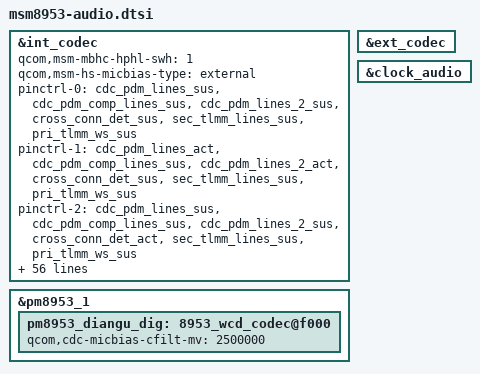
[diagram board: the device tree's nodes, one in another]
/*
 * Copyright (c) 2015-2016, The Linux Foundation. All rights reserved.
 *
 * This program is free software; you can redistribute it and/or modify
 * it under the terms of the GNU General Public License version 2 and
 * only version 2 as published by the Free Software Foundation.
 *
 * This program is distributed in the hope that it will be useful,
 * but WITHOUT ANY WARRANTY; without even the implied warranty of
 * MERCHANTABILITY or FITNESS FOR A PARTICULAR PURPOSE.  See the
 * GNU General Public License for more details.
 */


&int_codec {
	/delete-property/ qcom,cdc-us-euro-gpios;
	qcom,msm-mbhc-hphl-swh = <1>;
	qcom,msm-hs-micbias-type = "external";

	pinctrl-0 = <&cdc_pdm_lines_sus &cdc_pdm_comp_lines_sus
		&cdc_pdm_lines_2_sus &cross_conn_det_sus
		&sec_tlmm_lines_sus &pri_tlmm_ws_sus>;
	pinctrl-1 = <&cdc_pdm_lines_act &cdc_pdm_comp_lines_sus
		&cdc_pdm_lines_2_act &cross_conn_det_sus
		&sec_tlmm_lines_sus &pri_tlmm_ws_sus>;
	pinctrl-2 = <&cdc_pdm_lines_sus &cdc_pdm_comp_lines_sus
		&cdc_pdm_lines_2_sus &cross_conn_det_act
		&sec_tlmm_lines_sus &pri_tlmm_ws_sus>;
	pinctrl-3 = <&cdc_pdm_lines_act &cdc_pdm_comp_lines_sus
		&cdc_pdm_lines_2_act &cross_conn_det_act
		&sec_tlmm_lines_sus &pri_tlmm_ws_sus>;
	pinctrl-4 = <&cdc_pdm_lines_sus &cdc_pdm_comp_lines_sus
		&cdc_pdm_lines_2_sus &cross_conn_det_sus
		&sec_tlmm_lines_act &pri_tlmm_ws_act>;
	pinctrl-5 = <&cdc_pdm_lines_act &cdc_pdm_comp_lines_sus
		&cdc_pdm_lines_2_act &cross_conn_det_sus
		&sec_tlmm_lines_act &pri_tlmm_ws_act>;
	pinctrl-6 = <&cdc_pdm_lines_sus &cdc_pdm_comp_lines_sus
		&cdc_pdm_lines_2_sus &cross_conn_det_act
		&sec_tlmm_lines_act &pri_tlmm_ws_act>;
	pinctrl-7 = <&cdc_pdm_lines_act &cdc_pdm_comp_lines_sus
		&cdc_pdm_lines_2_act &cross_conn_det_act
		&sec_tlmm_lines_act &pri_tlmm_ws_act>;
	pinctrl-8 = <&cdc_pdm_lines_sus &cdc_pdm_comp_lines_act
		&cdc_pdm_lines_2_sus &cross_conn_det_sus
		&sec_tlmm_lines_sus &pri_tlmm_ws_sus>;
	pinctrl-9 = <&cdc_pdm_lines_act &cdc_pdm_comp_lines_act
		&cdc_pdm_lines_2_act &cross_conn_det_sus
		&sec_tlmm_lines_sus &pri_tlmm_ws_sus>;
	pinctrl-10 = <&cdc_pdm_lines_sus &cdc_pdm_comp_lines_act
		&cdc_pdm_lines_2_sus &cross_conn_det_act
		&sec_tlmm_lines_sus &pri_tlmm_ws_sus>;
	pinctrl-11 = <&cdc_pdm_lines_act &cdc_pdm_comp_lines_act
		&cdc_pdm_lines_2_act &cross_conn_det_act
		&sec_tlmm_lines_sus &pri_tlmm_ws_sus>;
	pinctrl-12 = <&cdc_pdm_lines_sus &cdc_pdm_comp_lines_act
		&cdc_pdm_lines_2_sus &cross_conn_det_sus
		&sec_tlmm_lines_act &pri_tlmm_ws_act>;
	pinctrl-13 = <&cdc_pdm_lines_act &cdc_pdm_comp_lines_act
		&cdc_pdm_lines_2_act &cross_conn_det_sus
		&sec_tlmm_lines_act &pri_tlmm_ws_act>;
	pinctrl-14 = <&cdc_pdm_lines_sus &cdc_pdm_comp_lines_act
		&cdc_pdm_lines_2_sus &cross_conn_det_act
		&sec_tlmm_lines_act &pri_tlmm_ws_act>;
	pinctrl-15 = <&cdc_pdm_lines_act &cdc_pdm_comp_lines_act
		&cdc_pdm_lines_2_act &cross_conn_det_act
		&sec_tlmm_lines_act &pri_tlmm_ws_act>;

	asoc-codec = <&stub_codec>, <&pm8953_diangu_dig>, <&hdmi_dba>;
	asoc-codec-names = "msm-stub-codec.1", "cajon_codec",
						"msm-hdmi-dba-codec-rx";
	/delete-property/ asoc-wsa-codec-names;
	/delete-property/ asoc-wsa-codec-prefixes;
	/delete-property/ msm-vdd-wsa-switch-supply;
	/delete-property/ qcom,msm-vdd-wsa-switch-voltage;
	/delete-property/ qcom,msm-vdd-wsa-switch-current;
};

/*
//ZTEMT: fengxun added for AL3200
&pm8953_gpios {
	/delete-node/gpio@c000;
};
//ZTEMT: fengxun added for AL3200
*/

&ext_codec {
	/delete-property/ qcom,cdc-us-euro-gpios;
	/delete-property/ qcom,wsa-max-devs;
	/delete-property/ qcom,wsa-devs;
	/delete-property/ qcom,wsa-aux-dev-prefix;
};

//ZTEMT: fengxun added for AL3200
&clock_audio {
	/delete-property/ qcom,audio-ref-clk-gpio;
	/delete-property/ qcom,lpass-mclk-id;
	/delete-property/ clocks;
	/delete-property/ pinctrl-names;
	/delete-property/ pinctrl-0;
	/delete-property/ pinctrl-1;
};
//ZTEMT: fengxun added for AL3200

&pm8953_1 {
	pm8953_diangu_dig: 8953_wcd_codec@f000 {
                qcom,cdc-micbias-cfilt-mv = <2500000>;
	};

};

 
